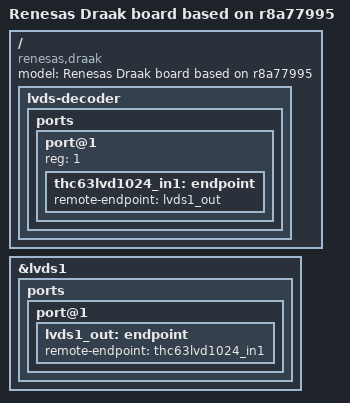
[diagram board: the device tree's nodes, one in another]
// SPDX-License-Identifier: GPL-2.0
/*
 * Device Tree Source for the Draak board with R-Car D3
 *
 * Copyright (C) 2016-2018 Renesas Electronics Corp.
 * Copyright (C) 2017 Glider bvba
 */

/dts-v1/;
#include "r8a77995.dtsi"
#include "draak.dtsi"

/ {
	model = "Renesas Draak board based on r8a77995";
	compatible = "renesas,draak", "renesas,r8a77995";

	lvds-decoder {
		ports {
			port@1 {
				reg = <1>;
				thc63lvd1024_in1: endpoint {
					remote-endpoint = <&lvds1_out>;
				};
			};
		};
	};
};

&lvds1 {
	ports {
		port@1 {
			lvds1_out: endpoint {
				remote-endpoint = <&thc63lvd1024_in1>;
			};
		};
	};
};
